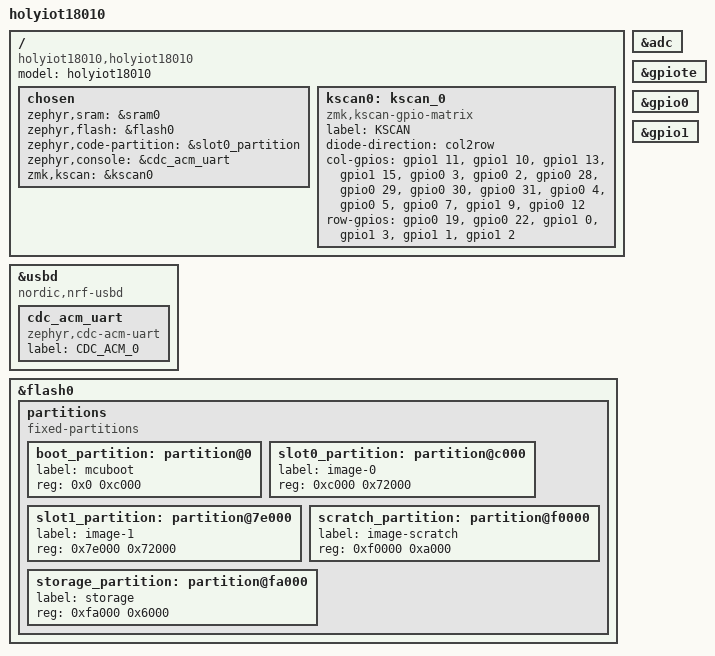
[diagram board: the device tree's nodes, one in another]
// Copyright (c) 2023 Nordic Semiconductor ASA
// SPDX-License-Identifier: Apache-2.0

/dts-v1/;
#include <nordic/nrf52840_qiaa.dtsi>
#include <dt-bindings/zmk/matrix_transform.h>

/ {
	model = "holyiot18010";
	compatible = "holyiot18010,holyiot18010";

	chosen {
		zephyr,sram = &sram0;
		zephyr,flash = &flash0;
		zephyr,code-partition = &slot0_partition;
        zephyr,console = &cdc_acm_uart;
        // zmk,battery = &vbatt;
		zmk,kscan = &kscan0;
	};
	
	// leds {
    //     compatible = "gpio-leds";
    //     red_led: led_0 {
    //         gpios = <&gpio0 30 GPIO_ACTIVE_HIGH>;
    //         label = "Red LED";
    //     };
    //     green_led: led_1 {
    //         gpios = <&gpio0 29 GPIO_ACTIVE_HIGH>;
    //         label = "Green LED";
    //     };
    //     blue_led: led_2 {
    //         gpios = <&gpio0 31 GPIO_ACTIVE_HIGH>;
    //         label = "Blue LED";
    //     };
    // };

	// vbatt: vbatt {
    //     compatible = "zmk,battery-voltage-divider";
    //     label = "BATTERY";
    //     io-channels = <&adc 0>;
    //     output-ohms = <1000000>;
    //     full-ohms = <(1000000 + 1000000)>;
    // };

	kscan0: kscan_0 {
        compatible = "zmk,kscan-gpio-matrix";
        label = "KSCAN";
        diode-direction = "col2row";

        col-gpios = <&gpio1 11 GPIO_ACTIVE_HIGH>
            , <&gpio1 10 GPIO_ACTIVE_HIGH>
            , <&gpio1 13 GPIO_ACTIVE_HIGH>
            , <&gpio1 15 GPIO_ACTIVE_HIGH>
            , <&gpio0 3 GPIO_ACTIVE_HIGH>
            , <&gpio0 2 GPIO_ACTIVE_HIGH>
            , <&gpio0 28 GPIO_ACTIVE_HIGH>
            , <&gpio0 29 GPIO_ACTIVE_HIGH>
            , <&gpio0 30 GPIO_ACTIVE_HIGH>
            , <&gpio0 31 GPIO_ACTIVE_HIGH>
            , <&gpio0 4 GPIO_ACTIVE_HIGH>
            , <&gpio0 5 GPIO_ACTIVE_HIGH>
            , <&gpio0 7 GPIO_ACTIVE_HIGH>
            , <&gpio1 9 GPIO_ACTIVE_HIGH>
            , <&gpio0 12 GPIO_ACTIVE_HIGH>
            ;
        
        row-gpios = <&gpio0 19 (GPIO_ACTIVE_HIGH | GPIO_PULL_DOWN)>
            , <&gpio0 22 (GPIO_ACTIVE_HIGH | GPIO_PULL_DOWN)>
            , <&gpio1 0 (GPIO_ACTIVE_HIGH | GPIO_PULL_DOWN)>
            , <&gpio1 3 (GPIO_ACTIVE_HIGH | GPIO_PULL_DOWN)>
            , <&gpio1 1 (GPIO_ACTIVE_HIGH | GPIO_PULL_DOWN)>
            , <&gpio1 2 (GPIO_ACTIVE_HIGH | GPIO_PULL_DOWN)>
			;
    };
};

&adc {
    status = "okay";
};

&gpiote {
    status = "okay";
};

&gpio0 {
    status = "okay";
};

&gpio1 {
    status = "okay";
};

&usbd {
    compatible = "nordic,nrf-usbd";
    status = "okay";
    cdc_acm_uart: cdc_acm_uart {
        compatible = "zephyr,cdc-acm-uart";
        label = "CDC_ACM_0";
    };
};

&flash0 {
	/*
     * For more information, see:
     * http://docs.zephyrproject.org/latest/devices/dts/flash_partitions.html
     */

	partitions {
		compatible = "fixed-partitions";
		#address-cells = <1>;
		#size-cells = <1>;

		boot_partition: partition@0 {
			label = "mcuboot";
			reg = <0x0 0xc000>;
		};
		slot0_partition: partition@c000 {
			label = "image-0";
			reg = <0xc000 0x72000>;
		};
		slot1_partition: partition@7e000 {
			label = "image-1";
			reg = <0x7e000 0x72000>;
		};
		scratch_partition: partition@f0000 {
			label = "image-scratch";
			reg = <0xf0000 0xa000>;
		};

		/*
         * The flash starting at 0x000ec000 and ending at
         * 0x000f3fff is reserved for use by the application.
         */

        /*
         * Storage partition will be used by FCB/LittleFS/NVS
         * if enabled.
         */
		storage_partition: partition@fa000 {
			label = "storage";
			reg = <0xfa000 0x6000>;
		};
	};
};
